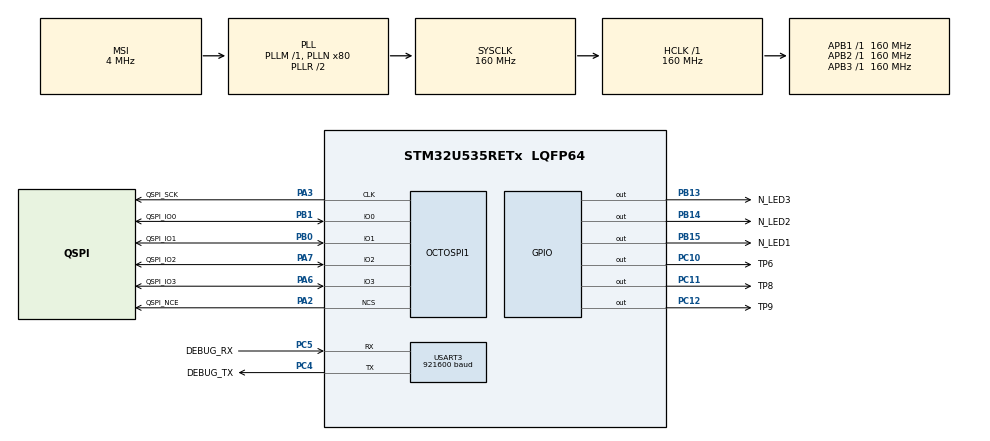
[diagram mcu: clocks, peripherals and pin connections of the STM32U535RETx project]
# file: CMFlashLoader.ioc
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CORTEX_M33_NS.userName=CORTEX_M33
Mcu.Family=STM32U5
Mcu.Name=STM32U535RETx
Mcu.Package=LQFP64
NVIC.PriorityGroup=NVIC_PRIORITYGROUP_4
OCTOSPI1.ClockPrescaler=1
OCTOSPI1.DeviceSize=26
OCTOSPI1.DeviceType=SPI_DEVICE_FLASH
OCTOSPI1.MemoryType=HAL_OSPI_MEMTYPE_MICRON
PA13\ (JTMS/SWDIO).Signal=DEBUG_JTMS-SWDIO
PA14\ (JTCK/SWCLK).Signal=DEBUG_JTCK-SWCLK
PA2.GPIO_Label=QSPI_NCE
PA2.Mode=quad_mode
PA2.Signal=OCTOSPI1_NCS
PA3.GPIO_Label=QSPI_SCK
PA3.Mode=quad_mode
PA3.Signal=OCTOSPI1_CLK
PA6.GPIO_Label=QSPI_IO3
PA6.Mode=quad_mode
PA6.Signal=OCTOSPI1_IO3
PA7.GPIO_Label=QSPI_IO2
PA7.Mode=quad_mode
PA7.Signal=OCTOSPI1_IO2
PB0.GPIO_Label=QSPI_IO1
PB0.Mode=quad_mode
PB0.Signal=OCTOSPI1_IO1
PB1.GPIO_Label=QSPI_IO0
PB1.Mode=quad_mode
PB1.Signal=OCTOSPI1_IO0
PB13.GPIO_Label=N_LED3
PB13.Signal=GPIO_Output
PB14.GPIO_Label=N_LED2
PB14.Signal=GPIO_Output
PB15.GPIO_Label=N_LED1
PB15.Signal=GPIO_Output
PC10.GPIO_Label=TP6
PC10.Signal=GPIO_Output
PC11.GPIO_Label=TP8
PC11.Signal=GPIO_Output
PC12.GPIO_Label=TP9
PC12.Signal=GPIO_Output
PC14-OSC32_IN\ (PC14).Mode=LSE-External-Oscillator
PC14-OSC32_IN\ (PC14).Signal=RCC_OSC32_IN
PC15-OSC32_OUT\ (PC15).Mode=LSE-External-Oscillator
PC15-OSC32_OUT\ (PC15).Signal=RCC_OSC32_OUT
PC4.GPIO_Label=DEBUG_TX
PC4.Mode=Asynchronous
PC4.Signal=USART3_TX
PC5.GPIO_Label=DEBUG_RX
PC5.Mode=Asynchronous
PC5.Signal=USART3_RX
ProjectManager.HeapSize=0x200
ProjectManager.StackSize=0x400
ProjectManager.TargetToolchain=STM32CubeIDE
RCC.ADCFreq_Value=16000000
RCC.AHBFreq_Value=160000000
RCC.APB1Freq_Value=160000000
RCC.APB1TimFreq_Value=160000000
RCC.APB2Freq_Value=160000000
RCC.APB2TimFreq_Value=160000000
RCC.APB3Freq_Value=160000000
RCC.CortexFreq_Value=160000000
RCC.DACCLockSelectionVirtual=RCC_DAC1CLKSOURCE_LSI
RCC.DACCLockSelectionVirtualString=RCC_DAC1CLKSOURCE_LSI
RCC.EPOD_VALUE=4000000
RCC.HCLKFreq_Value=160000000
RCC.HSE_VALUE=16000000
RCC.HSI48_VALUE=48000000
RCC.HSI_VALUE=16000000
RCC.LSIDIV_VALUE=32000
RCC.MSI_VALUE=4000000
RCC.OCTOSPIMCLockSelection=RCC_OSPICLKSOURCE_PLL2
RCC.PLL2N=120
RCC.PLL2Q=6
RCC.PLLFRACN=0
RCC.PLLN=80
RCC.RTCClockSelection=RCC_RTCCLKSOURCE_LSE
RCC.SYSCLKFreq_VALUE=160000000
RCC.SYSCLKSource=RCC_SYSCLKSOURCE_PLLCLK
RCC.USBFreq_Value=48000000
RCC.VCOOutputFreq_Value=320000000
USART3.BaudRate=921600
USART3.VirtualMode-Asynchronous=VM_ASYNC
VP_DCACHE1_VS_DCACHE.Mode=DCACHE_Activate
VP_ICACHE_VS_ICACHE.Mode=DirectMappedCache
VP_LPBAMQUEUE_VS_QUEUE.Mode=QUEUEMODE
VP_LPBAM_VS_SIG1.Mode=SmartRun
VP_LPBAM_VS_SIG4.Mode=LPDMA1
VP_MEMORYMAP_VS_MEMORYMAP.Mode=CurAppReg
VP_PWR_VS_SECSignals.Mode=Security/Privilege
board=custom

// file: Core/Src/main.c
/* USER CODE BEGIN Header */
/**
  ******************************************************************************
  * @file           : main.c
  * @brief          : Main program body
  ******************************************************************************
  * @attention
  *
  * Copyright (c) 2024 STMicroelectronics.
  * All rights reserved.
  *
  * This software is licensed under terms that can be found in the LICENSE file
  * in the root directory of this software component.
  * If no LICENSE file comes with this software, it is provided AS-IS.
  *
  ******************************************************************************
  */
/* USER CODE END Header */
#include "main.h"
#include "dcache.h"
#include "icache.h"
#include "memorymap.h"
#include "octospi.h"
#include "usart.h"
#include "gpio.h"

/* USER CODE BEGIN Includes */
#include "FlashDriver.h"
/* USER CODE END Includes */

void SystemClock_Config(void);

int main(void)
{

  /* MCU Configuration--------------------------------------------------------*/

  /* Reset of all peripherals, Initializes the Flash interface and the Systick. */
  HAL_Init();

  /* Configure the system clock */
  SystemClock_Config();

  /* Initialize all configured peripherals */
  MX_GPIO_Init();
  MX_OCTOSPI1_Init();
  MX_USART3_UART_Init();
  MX_ICACHE_Init();
  MX_DCACHE1_Init();
  /* USER CODE BEGIN 2 */

  FlashTest();

  /* USER CODE END 2 */

  /* Infinite loop */
  while (1)
  {

  }
}

void SystemClock_Config(void)
{
  RCC_OscInitTypeDef RCC_OscInitStruct = {0};
  RCC_ClkInitTypeDef RCC_ClkInitStruct = {0};

  /** Configure the main internal regulator output voltage
  */
  if (HAL_PWREx_ControlVoltageScaling(PWR_REGULATOR_VOLTAGE_SCALE1) != HAL_OK)
  {
    Error_Handler();
  }

  /** Initializes the CPU, AHB and APB buses clocks
  */
  RCC_OscInitStruct.OscillatorType = RCC_OSCILLATORTYPE_MSI;
  RCC_OscInitStruct.MSIState = RCC_MSI_ON;
  RCC_OscInitStruct.MSICalibrationValue = RCC_MSICALIBRATION_DEFAULT;
  RCC_OscInitStruct.MSIClockRange = RCC_MSIRANGE_4;
  RCC_OscInitStruct.PLL.PLLState = RCC_PLL_ON;
  RCC_OscInitStruct.PLL.PLLSource = RCC_PLLSOURCE_MSI;
  RCC_OscInitStruct.PLL.PLLMBOOST = RCC_PLLMBOOST_DIV1;
  RCC_OscInitStruct.PLL.PLLM = 1;
  RCC_OscInitStruct.PLL.PLLN = 80;
  RCC_OscInitStruct.PLL.PLLP = 2;
  RCC_OscInitStruct.PLL.PLLQ = 2;
  RCC_OscInitStruct.PLL.PLLR = 2;
  RCC_OscInitStruct.PLL.PLLRGE = RCC_PLLVCIRANGE_0;
  RCC_OscInitStruct.PLL.PLLFRACN = 0;
  if (HAL_RCC_OscConfig(&RCC_OscInitStruct) != HAL_OK)
  {
    Error_Handler();
  }

  /** Initializes the CPU, AHB and APB buses clocks
  */
  RCC_ClkInitStruct.ClockType = RCC_CLOCKTYPE_HCLK|RCC_CLOCKTYPE_SYSCLK
                              |RCC_CLOCKTYPE_PCLK1|RCC_CLOCKTYPE_PCLK2
                              |RCC_CLOCKTYPE_PCLK3;
  RCC_ClkInitStruct.SYSCLKSource = RCC_SYSCLKSOURCE_PLLCLK;
  RCC_ClkInitStruct.AHBCLKDivider = RCC_SYSCLK_DIV1;
  RCC_ClkInitStruct.APB1CLKDivider = RCC_HCLK_DIV1;
  RCC_ClkInitStruct.APB2CLKDivider = RCC_HCLK_DIV1;
  RCC_ClkInitStruct.APB3CLKDivider = RCC_HCLK_DIV1;

  if (HAL_RCC_ClockConfig(&RCC_ClkInitStruct, FLASH_LATENCY_4) != HAL_OK)
  {
    Error_Handler();
  }
}

void Error_Handler(void)
{
  __disable_irq();
  while (1)
  {
  }
}
